AUTOSAR XML (schema 4-2-2)
package /Components
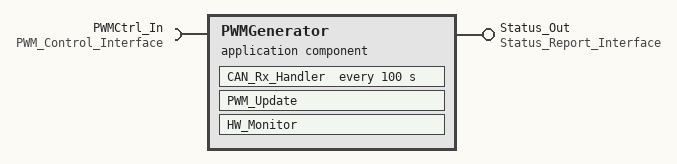
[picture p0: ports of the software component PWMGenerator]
  application sw component type PWMGenerator
    provide port Status_Out: provided-interface=Status_Report_Interface
    require port PWMCtrl_In: required-interface=PWM_Control_Interface
    behavior PWMGenerator_Behavior
      data received event PWM_Command_Received_Event: start-on-event=CAN_Rx_Handler
      timing event PWM_Hardware_Cycle_Event: start-on-event=CAN_Rx_Handler, period=10
      timing event HW_Monitor_Cycle_Event: start-on-event=CAN_Rx_Handler, period=100
      runnable PWM_Update: minimum-start-interval=10, symbol=Runnable_PWM_Update
        data-read-access:
          access Read_Current_Duty: accessed-variable={autosar-variable-in-impl-datatype={port-prototype=Status_Out, target-data-prototype=CurrentDutyImpl}, autosar-variable=Status_Out.CurrentDuty}
        data-receive-point-by-arguments:
          access Receive_PWM_Command: accessed-variable={autosar-variable-in-impl-datatype={port-prototype=PWMCtrl_In, target-data-prototype=PWMCommandImpl}, autosar-variable=PWMCtrl_In.PWM_Command}
        data-send-points:
          access Send_HW_Status: accessed-variable={autosar-variable-in-impl-datatype={port-prototype=Status_Out, target-data-prototype=StatusImpl}, autosar-variable=Status_Out.LampStatus}
        data-write-access:
          access Write_HW_Register: accessed-variable={autosar-variable-in-impl-datatype={port-prototype=Status_Out, target-data-prototype=HW_Register}, autosar-variable=Status_Out.OutputRegister}
      runnable HW_Monitor: minimum-start-interval=100, symbol=Runnable_HW_Monitor
        data-read-access:
          access Read_Hardware_Metrics: accessed-variable={autosar-variable-in-impl-datatype={port-prototype=Status_Out, target-data-prototype=HwMetricsImpl}, autosar-variable=Status_Out.DriverMetrics}
        data-receive-point-by-arguments:
          access No_Args: accessed-variable={autosar-variable-in-impl-datatype={port-prototype=Status_Out, target-data-prototype=NoArgsImpl}, autosar-variable=Status_Out.NoArgs}
        data-send-points:
          access Report_Status: accessed-variable={autosar-variable-in-impl-datatype={port-prototype=Status_Out, target-data-prototype=StatusImpl}, autosar-variable=Status_Out.DriverFaultFlag}
        data-write-access:
          access Apply_Safety_Action: accessed-variable={autosar-variable-in-impl-datatype={port-prototype=Status_Out, target-data-prototype=OutputDisableImpl}, autosar-variable=Status_Out.OutputDisable}
